# StarFive VisionFive 2 v1.2A register map
File version: 0.1
Registers are 32-bit, read-write, reset 0x0 unless marked. A register's access mark holds for its fields unless they carry their own. Offsets are from the block's base; [hi:lo] are bit positions; {n}, {i} and the like mark numbered series.

## clint — From starfive,jh7110-clint, peripheral generator
Base 0x02000000
{0x0+4i} msip_{i} (i=0..4) — MSIP Register for hart {i}
  [0] control
{0x4000+8i} mtimecmp_{i} 64-bit (i=0..4) — MTIMECMP Register for hart {i}
  [63:0] cycles
0xBFF8 mtime 64-bit
  [63:0] cycles

## plic — From starfive,jh7110-plic, peripheral generator
Base 0x0C000000
{0x0+4i} priority_{i} (i=1..136) — PRIORITY Register for interrupt id {i}
  [31:0] priority
{0x1000+4i} pending_{i} (i=0..3) — PENDING Register for interrupt ids {32i+31} to {32i}
  [31:0] pending
0x1010 pending_4 — PENDING Register for interrupt ids 136 to 128
  [31:0] pending
{0x2000+0x80*i} enable_0_{i} (i=0..4) — ENABLE Register for interrupt ids 31 to 0 for hart {i}
  [31:0] enable
{0x2004+0x80*i} enable_1_{i} (i=0..4) — ENABLE Register for interrupt ids 63 to 32 for hart {i}
  [31:0] enable
{0x2008+0x80*i} enable_2_{i} (i=0..4) — ENABLE Register for interrupt ids 95 to 64 for hart {i}
  [31:0] enable
{0x200C+0x80*i} enable_3_{i} (i=0..4) — ENABLE Register for interrupt ids 127 to 96 for hart {i}
  [31:0] enable
{0x2010+0x80*i} enable_4_{i} (i=0..4) — ENABLE Register for interrupt ids 136 to 128 for hart {i}
  [31:0] enable
{0x200000+0x1000*i} threshold_{i} (i=0..4) — PRIORITY THRESHOLD Register for hart {i}
  [31:0] priority
{0x200004+0x1000*i} claimplete_{i} (i=0..4) — CLAIM and COMPLETE Register for hart {i}
  [31:0] claimplete

## dmc_ctrl — From starfive,jh7110-dmc-ctrl, peripheral generator
Base 0x15700000
{0x0+4i} csr[{i}] (i=0..1023) — DDR Memory Control CSR register
{0x1000+4i} sec[{i}] (i=0..2047) — DDR Memory Control SEC register

## dmc_phy — From starfive,jh7110-dmc-phy, peripheral generator
Base 0x13000000
{0x0+4i} csr[{i}] (i=0..2047) — DDR Memory Control PHY CSR
{0x2000+4i} base[{i}] (i=0..2047) — DDR Memory Control PHY Base register
{0x4000+4i} ac_base[{i}] (i=0..2047) — DDR Memory Control PHY AC Base register

## pwm — From starfive,jh7110-pwm, peripheral generator
Base 0x120D0000
0x00 cntr reset not defined — PTC counter register
  [31:0] cntr — PWM PTC counter
0x04 hrc reset not defined — PTC duty-cycle register
  [31:0] hrc — PWM PTC duty-cycle value
0x08 lrc reset not defined — PTC period register
  [31:0] lrc — PWM PTC period value
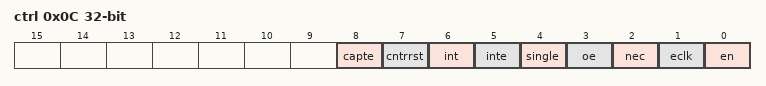
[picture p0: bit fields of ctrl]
0x0C ctrl reset not defined — PTC control register
  [8] capte — PWM PTC capte
  [7] cntrrst — PWM PTC counter reset
  [6] int — PWM PTC interrupt
  [5] inte — PWM PTC interrupt enable
  [4] single — PWM PTC single
  [3] oe — PWM PTC oe
  [2] nec — PWM PTC nec
  [1] eclk — PWM PTC enable clock
  [0] en — PWM PTC enable

## trng — From starfive,jh7110-trng, peripheral generator
Base 0x1600C000
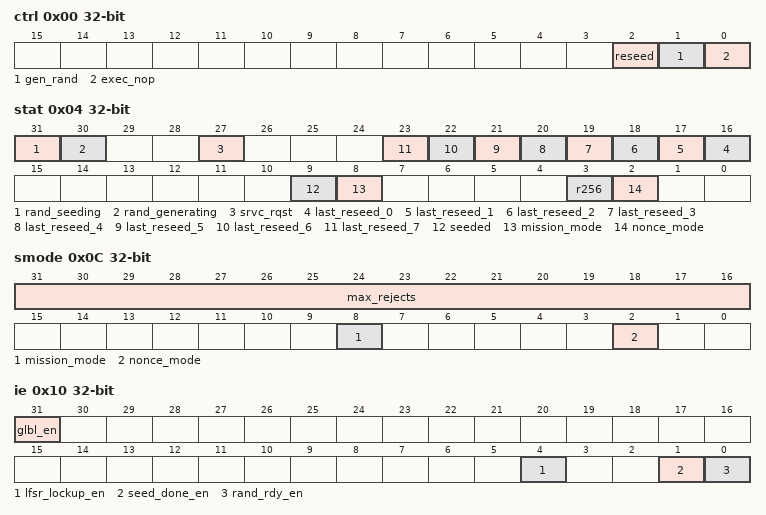
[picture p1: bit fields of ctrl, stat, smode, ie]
0x00 ctrl — TRNG CTRL Register
  [2] reseed — Reseed the TRNG from noise sources
  [1] gen_rand — Generate a random number
  [0] exec_nop — Execute a NOP instruction
0x04 stat — TRNG STAT Register
  [31] rand_seeding ro — TRNG Random Number Seeding Status
  [30] rand_generating ro — TRNG Random Number Generating Status
  [27] srvc_rqst ro — TRNG Service Request
  [n+16] last_reseed_{n} ro (n=0..7) — TRNG Last Reseed {n} status
  [9] seeded ro — TRNG Seeded operating mode
  [8] mission_mode ro — TRNG Mission Mode operating mode
  [3] r256 ro — TRNG 256-bit random number operating mode
  [2] nonce_mode ro — TRNG Nonce operating mode
0x08 mode — TRNG MODE Register
  [3] r256 — 256-bit operation mode: 0 - 128-bit mode, 1 - 256-bit mode
0x0C smode — TRNG SMODE Register
  [31:16] max_rejects — TRNG Maximum Rejects
  [8] mission_mode — Mission operation mode
  [2] nonce_mode — Nonce operation mode
0x10 ie — TRNG Interrupt Enable Register
  [31] glbl_en — Global Enable
  [4] lfsr_lockup_en — LFSR Lockup Enable
  [1] seed_done_en — Seed Done Enable
  [0] rand_rdy_en — RAND Ready Enable
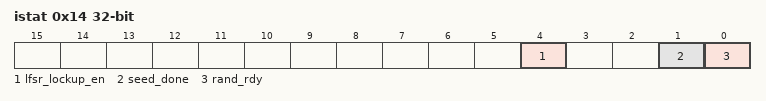
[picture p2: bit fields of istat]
0x14 istat — TRNG Interrupt Status Register
  [4] lfsr_lockup_en ro — LFSR Lockup Enable
  [1] seed_done ro — Seed Done Enable
  [0] rand_rdy ro — RAND Ready Enable
{0x20+4i} rand_{i} (i=0..7) — TRNG RAND {i} Status Register
  [31:0] rand ro — Random number bits
0x60 auto_rqsts — Auto-reseeding after random number requests by host reaches specified counter: 0 - disable counter, other - reload value for internal counter
  [31:0] rqsts — Threshold number of reseed requests for auto-reseed counter
0x64 auto_age — Auto-reseeding after specified timer countdowns to 0: 0 - disable timer, other - reload value for internal timer
  [31:0] age — Countdown value for auto-reseed timer
